# STM32G534xx register map
File version: 1.0
Registers are 32-bit, read-write, reset 0x0 unless marked. A register's access mark holds for its fields unless they carry their own. Offsets are from the block's base; [hi:lo] are bit positions; {n}, {i} and the like mark numbered series.

## RCC — Reset and clock control (RCC)
Base 0x44020C00
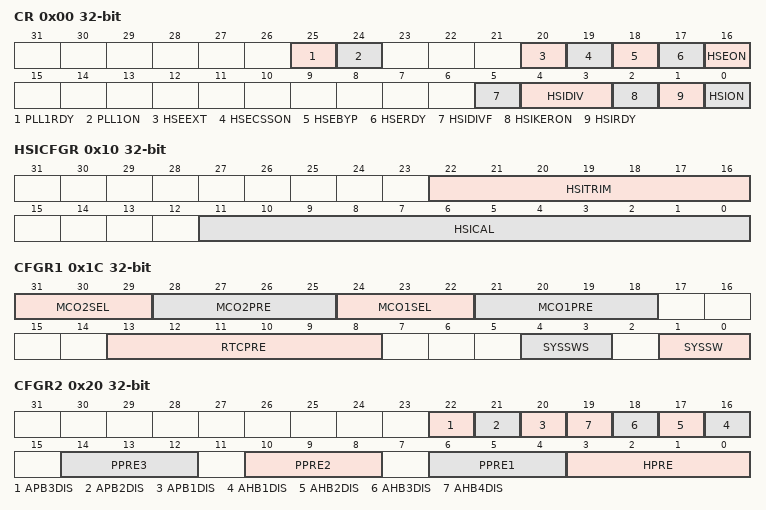
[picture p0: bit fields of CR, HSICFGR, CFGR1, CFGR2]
0x00 CR — RCC clock control register
  [25] PLL1RDY — PLL1 clock ready flag
  [24] PLL1ON — PLL1 enable
  [20] HSEEXT
  [19] HSECSSON
  [18] HSEBYP — HSE clock bypass
  [17] HSERDY — HSE clock ready flag
  [16] HSEON — HSE clock enable
  [5] HSIDIVF — HSI divider flag
  [4:3] HSIDIV — HSI clock divider
  [2] HSIKERON — HSI clock enable in Stop mode
  [1] HSIRDY — HSI clock ready flag
  [0] HSION — HSI clock enable
0x10 HSICFGR — RCC HSI calibration register
  [22:16] HSITRIM — HSI clock trimming
  [11:0] HSICAL — HSI clock calibration
0x1C CFGR1 — RCC clock configuration register1
  [31:29] MCO2SEL — microcontroller clock output 2
  [28:25] MCO2PRE — MCO2 prescaler
  [24:22] MCO1SEL — Microcontroller clock output 1
  [21:18] MCO1PRE — MCO1 prescaler
  [13:8] RTCPRE
  [4:3] SYSSWS — system clock switch status
  [1:0] SYSSW
0x20 CFGR2 — RCC CPU domain clock configuration register 2
  [22] APB3DIS — APB3 clock disable value
  [21] APB2DIS — APB2 clock disable value
  [20] APB1DIS — APB1 clock disable value
  [n+15] AHB{n}DIS (n=1..4) — AHB{n} clock disable
  [14:12] PPRE3 — APB low-speed prescaler (APB3)
  [10:8] PPRE2 — APB high-speed prescaler (APB2)
  [6:4] PPRE1 — APB low-speed prescaler (APB1)
  [3:0] HPRE — AHB prescaler
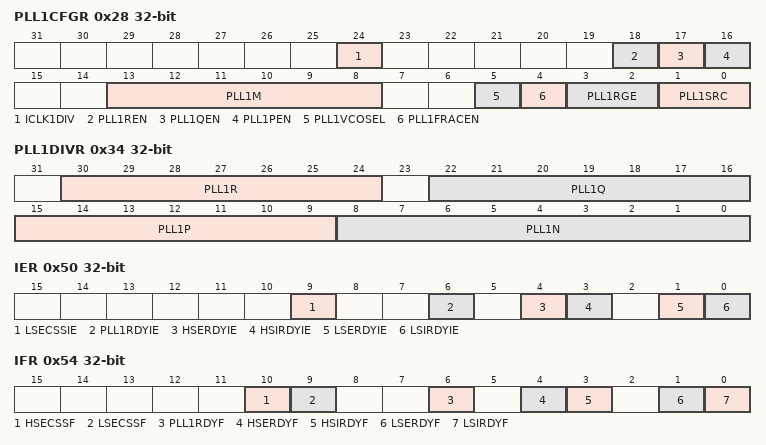
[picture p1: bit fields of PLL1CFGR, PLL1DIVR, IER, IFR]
0x28 PLL1CFGR — RCC PLL clock source selection register
  [24] ICLK1DIV — Intermediate clock 1 division
  [18] PLL1REN
  [17] PLL1QEN — PLL1 DIVQ divider output enable
  [16] PLL1PEN — PLL1 DIVP divider output enable
  [13:8] PLL1M — Prescaler for PLL1
  [5] PLL1VCOSEL — PLL1 VCO selection
  [4] PLL1FRACEN — PLL1 fractional latch enable
  [3:2] PLL1RGE — PLL1 input frequency range
  [1:0] PLL1SRC
0x34 PLL1DIVR — RCC PLL1 divider register
  [30:24] PLL1R — PLL1 DIVR division factor
  [22:16] PLL1Q — PLL1 DIVQ division factor
  [15:9] PLL1P — PLL1 DIVP division factor
  [8:0] PLL1N
0x38 PLL1FRACR — RCC PLL1 fractional divider register
  [15:3] PLL1FRACN
0x50 IER — RCC interrupt enable register
  [9] LSECSSIE
  [6] PLL1RDYIE — PLL1 ready interrupt enable
  [4] HSERDYIE — HSE ready interrupt enable
  [3] HSIRDYIE — HSI ready interrupt enable
  [1] LSERDYIE — LSE ready interrupt enable
  [0] LSIRDYIE — LSI ready interrupt enable
0x54 IFR ro — RCC interrupt flag register
  [10] HSECSSF
  [9] LSECSSF
  [6] PLL1RDYF — PLL1 ready interrupt flag
  [4] HSERDYF — HSE ready interrupt flag
  [3] HSIRDYF — HSI ready interrupt flag
  [1] LSERDYF — LSE ready interrupt flag
  [0] LSIRDYF — LSI ready interrupt flag
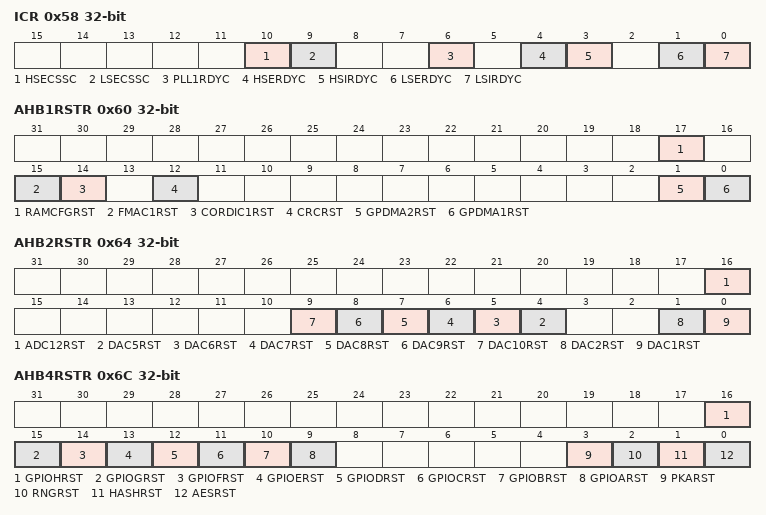
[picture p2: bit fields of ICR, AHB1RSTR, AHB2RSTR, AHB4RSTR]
0x58 ICR — RCC Interrupt clear register
  [10] HSECSSC
  [9] LSECSSC
  [6] PLL1RDYC — PLL1 ready interrupt clear
  [4] HSERDYC — HSE ready interrupt clear
  [3] HSIRDYC — HSI ready interrupt clear
  [1] LSERDYC — LSE ready interrupt clear
  [0] LSIRDYC — LSI ready interrupt clear
0x60 AHB1RSTR — RCC AHB1 reset register
  [17] RAMCFGRST — RAMCFG block reset
  [15] FMAC1RST — FMAC1 block reset
  [14] CORDIC1RST — CORDIC1 block reset
  [12] CRCRST
  [1] GPDMA2RST — GPDMA2 block reset
  [0] GPDMA1RST — GPDMA1 block reset
0x64 AHB2RSTR — RCC AHB2 peripheral reset register
  [16] ADC12RST — ADC1 and 2 blocks reset
  [n-1] DAC{n}RST (n=5..10) — DAC{n} block reset
  [1] DAC2RST — DAC2 block reset
  [0] DAC1RST — DAC1 block reset
0x6C AHB4RSTR — RCC AHB4 peripheral reset register
  [16] GPIOHRST — GPIOH block reset
  [15] GPIOGRST — GPIOG block reset
  [14] GPIOFRST — GPIOF block reset
  [13] GPIOERST — GPIOE block reset
  [12] GPIODRST — GPIOD block reset
  [11] GPIOCRST — GPIOC block reset
  [10] GPIOBRST — GPIOB block reset
  [9] GPIOARST — GPIOA block reset
  [3] PKARST — PKA block reset
  [2] RNGRST — RNG block reset
  [1] HASHRST — HASH block reset
  [0] AESRST — AES block reset
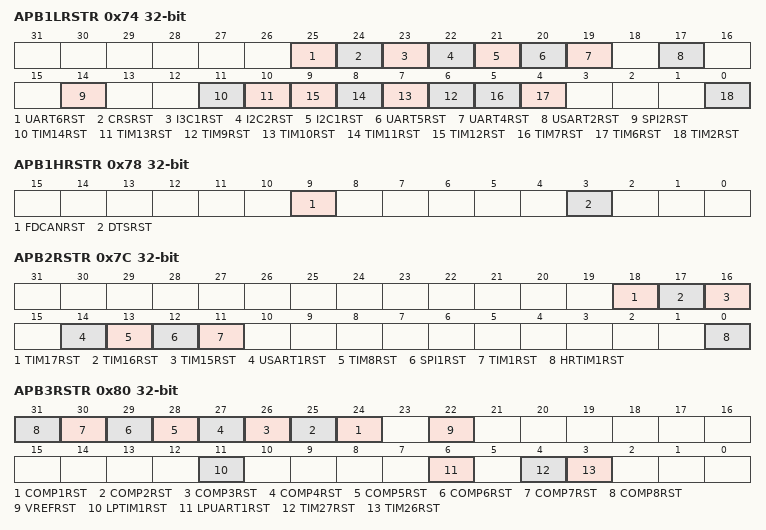
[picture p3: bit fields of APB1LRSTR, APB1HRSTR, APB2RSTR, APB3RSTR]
0x74 APB1LRSTR — RCC APB1 peripheral low reset register
  [25] UART6RST — UART6 block reset
  [24] CRSRST — CRS block reset
  [23] I3C1RST — I3C1 block reset
  [22] I2C2RST — I2C2 block reset
  [21] I2C1RST — I2C1 block reset
  [20] UART5RST — UART5 block reset
  [19] UART4RST — UART4 block reset
  [17] USART2RST — USART2 block reset
  [14] SPI2RST — SPI2 block reset
  [11] TIM14RST — TIM14 block reset
  [10] TIM13RST — TIM13 block reset
  [n-3] TIM{n}RST (n=9..12) — TIM12 block reset
  [5] TIM7RST — TIM7 block reset
  [4] TIM6RST — TIM6 block reset
  [0] TIM2RST — TIM2 block reset
0x78 APB1HRSTR — RCC APB1 peripheral high reset register
  [9] FDCANRST
  [3] DTSRST — DTS block reset
0x7C APB2RSTR — RCC APB2 peripheral reset register
  [18] TIM17RST — TIM17 block reset
  [17] TIM16RST — TIM16 block reset
  [16] TIM15RST — TIM15 block reset
  [14] USART1RST — USART1 block reset
  [13] TIM8RST — TIM8 block reset
  [12] SPI1RST — SPI1 block reset
  [11] TIM1RST — TIM1 block reset
  [0] HRTIM1RST — HRTIM1 block reset
0x80 APB3RSTR — RCC APB3 peripheral reset register
  [n+23] COMP{n}RST (n=1..8) — COMP{n} block reset
  [22] VREFRST — VREFBUF block reset
  [11] LPTIM1RST — LPTIM1 block reset
  [6] LPUART1RST — LPUART1 block reset
  [4] TIM27RST — TIM27 block reset
  [3] TIM26RST — TIM26 block reset
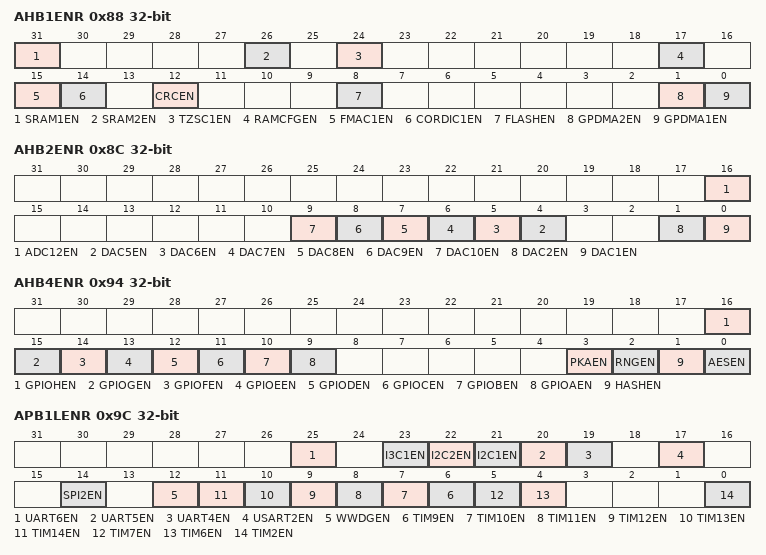
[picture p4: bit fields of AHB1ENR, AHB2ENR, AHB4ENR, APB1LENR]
0x88 AHB1ENR — RCC AHB1 peripheral clock enable register
  [31] SRAM1EN — SRAM1 clock enable
  [26] SRAM2EN — SRAM2 clock enable
  [24] TZSC1EN — TZSC1 clock enable
  [17] RAMCFGEN — RAMCFG clock enable
  [15] FMAC1EN — FMAC1 clock enable
  [14] CORDIC1EN — CORDIC1 clock enable
  [12] CRCEN — CRC clock enable
  [8] FLASHEN
  [1] GPDMA2EN — GPDMA2 clock enable
  [0] GPDMA1EN — GPDMA1 clock enable
0x8C AHB2ENR — RCC AHB2 peripheral clock enable register
  [16] ADC12EN
  [n-1] DAC{n}EN (n=5..10) — DAC{n} clock enable
  [1] DAC2EN — DAC2 clock enable
  [0] DAC1EN — DAC1 clock enable
0x90 AHB3ENR — RCC AHB3 peripheral clock enable register
  [21] DBGCKEN — DBG clock enable
0x94 AHB4ENR — RCC AHB4 peripheral clock enable register
  [16] GPIOHEN — GPIOH clock enable
  [15] GPIOGEN — GPIOG clock enable
  [14] GPIOFEN — GPIOF clock enable
  [13] GPIOEEN — GPIOE clock enable
  [12] GPIODEN — GPIOD clock enable
  [11] GPIOCEN — GPIOC clock enable
  [10] GPIOBEN — GPIOB clock enable
  [9] GPIOAEN — GPIOA clock enable
  [3] PKAEN — PKA clock enable
  [2] RNGEN — RNG clock enable
  [1] HASHEN — HASH clock enable
  [0] AESEN — AES clock enable
0x9C APB1LENR — RCC APB1 peripheral clock enable register
  [25] UART6EN — UART6 clock enable
  [23] I3C1EN — I3C1 clock enable
  [22] I2C2EN — I2C2 clock enable
  [21] I2C1EN — I2C1 clock enable
  [20] UART5EN — UART5 clock enable
  [19] UART4EN — UART4 clock enable
  [17] USART2EN — USART2 clock enable
  [14] SPI2EN — SPI2 clock enable
  [12] WWDGEN — WWDG clock enable
  [n-3] TIM{n}EN (n=9..14) — TIM{n} clock enable
  [5] TIM7EN — TIM7 clock enable
  [4] TIM6EN — TIM6 clock enable
  [0] TIM2EN — TIM2 clock enable
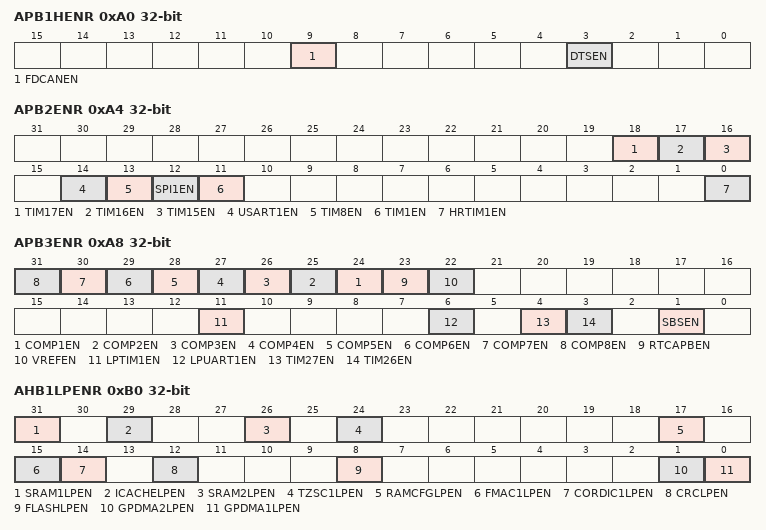
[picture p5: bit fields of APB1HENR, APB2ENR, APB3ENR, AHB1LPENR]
0xA0 APB1HENR — RCC APB1 peripheral clock enable register
  [9] FDCANEN
  [3] DTSEN — DTS clock enable
0xA4 APB2ENR — RCC APB2 peripheral clock enable register
  [18] TIM17EN — TIM17 clock enable
  [17] TIM16EN — TIM16 clock enable
  [16] TIM15EN — TIM15 clock enable
  [14] USART1EN — USART1 clock enable
  [13] TIM8EN — TIM8 clock enable
  [12] SPI1EN — SPI1 clock enable
  [11] TIM1EN — TIM1 clock enable
  [0] HRTIM1EN — HRTIM1 clock enable
0xA8 APB3ENR — RCC APB3 peripheral clock enable register
  [n+23] COMP{n}EN (n=1..8) — COMP{n} clock enable
  [23] RTCAPBEN — RTC APB interface clock enable
  [22] VREFEN — VREFBUF clock enable
  [11] LPTIM1EN — LPTIM1 clock enable
  [6] LPUART1EN — LPUART1 clock enable
  [4] TIM27EN — TIM27 clock enable
  [3] TIM26EN — TIM26 clock enable
  [1] SBSEN — SBS clock enable
0xB0 AHB1LPENR — RCC AHB1 peripheral low-power clock enable register
  [31] SRAM1LPEN, [29] ICACHELPEN, [26] SRAM2LPEN, [24] TZSC1LPEN, [17] RAMCFGLPEN, [15] FMAC1LPEN, [14] CORDIC1LPEN, [12] CRCLPEN, [8] FLASHLPEN, [1] GPDMA2LPEN, [0] GPDMA1LPEN
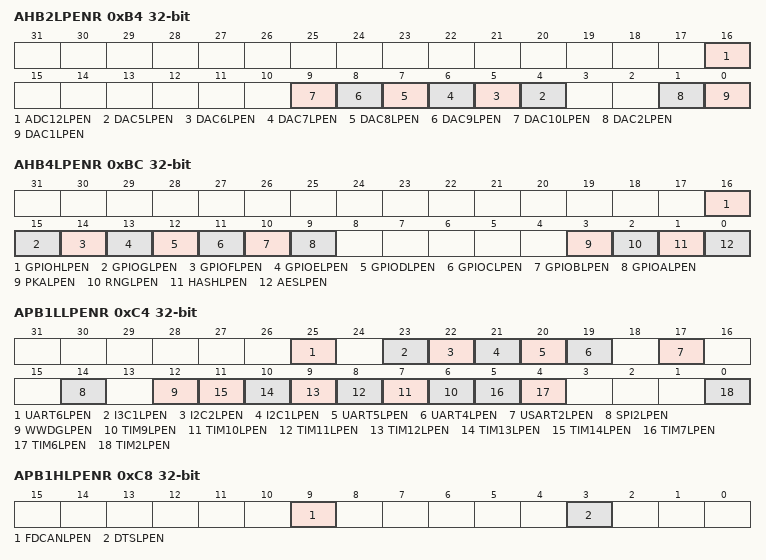
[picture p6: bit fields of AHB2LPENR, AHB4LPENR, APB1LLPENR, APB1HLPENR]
0xB4 AHB2LPENR — RCC AHB2 peripheral low-power clock enable register
  [16] ADC12LPEN, [n-1] DAC{n}LPEN (n=5..10), [1] DAC2LPEN, [0] DAC1LPEN
0xB8 AHB3LPENR — RCC AHB3 peripheral low-power clock enable register
  [21] DBGCKLPEN
0xBC AHB4LPENR — RCC AHB4 peripheral low-power clock enable register
  [16] GPIOHLPEN, [15] GPIOGLPEN, [14] GPIOFLPEN, [13] GPIOELPEN, [12] GPIODLPEN, [11] GPIOCLPEN, [10] GPIOBLPEN, [9] GPIOALPEN, [3] PKALPEN, [2] RNGLPEN, [1] HASHLPEN, [0] AESLPEN
0xC4 APB1LLPENR — RCC APB1 peripheral low-power clock enable register
  [25] UART6LPEN, [23] I3C1LPEN, [22] I2C2LPEN, [21] I2C1LPEN, [20] UART5LPEN, [19] UART4LPEN, [17] USART2LPEN, [14] SPI2LPEN, [12] WWDGLPEN, [n-3] TIM{n}LPEN (n=9..14), [5] TIM7LPEN, [4] TIM6LPEN, [0] TIM2LPEN
0xC8 APB1HLPENR — RCC APB1 peripheral low-power clock enable register
  [9] FDCANLPEN, [3] DTSLPEN
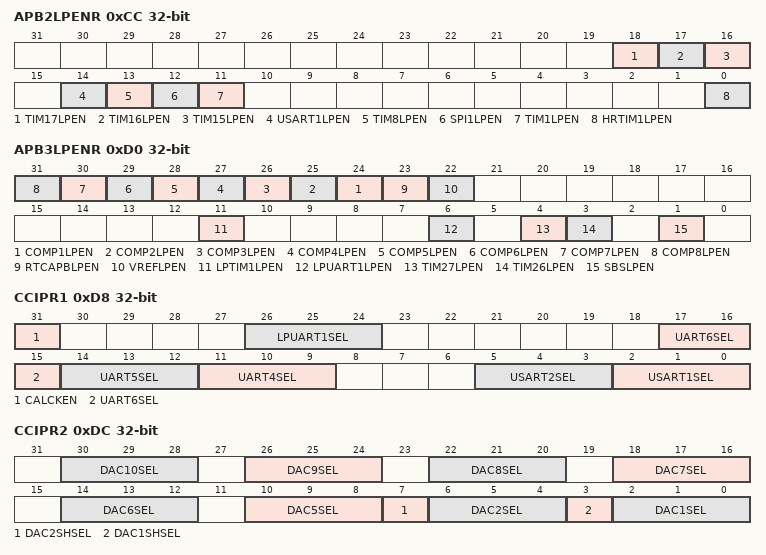
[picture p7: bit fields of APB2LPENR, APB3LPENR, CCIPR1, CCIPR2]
0xCC APB2LPENR — RCC APB2 peripheral low-power clock enable register
  [18] TIM17LPEN, [17] TIM16LPEN, [16] TIM15LPEN, [14] USART1LPEN, [13] TIM8LPEN, [12] SPI1LPEN, [11] TIM1LPEN, [0] HRTIM1LPEN
0xD0 APB3LPENR — RCC APB3 peripheral low-power clock enable register
  [n+23] COMP{n}LPEN (n=1..8), [23] RTCAPBLPEN, [22] VREFLPEN, [11] LPTIM1LPEN, [6] LPUART1LPEN, [4] TIM27LPEN, [3] TIM26LPEN, [1] SBSLPEN
0xD8 CCIPR1 — RCC kernel clock configuration register
  [31] CALCKEN — Calibration clock enable
  [26:24] LPUART1SEL
  [17:15] UART6SEL
  [14:12] UART5SEL
  [11:9] UART4SEL
  [5:3] USART2SEL
  [2:0] USART1SEL
0xDC CCIPR2 — RCC kernel clock configuration register
  [4n-10:4n-12] DAC{n}SEL (n=5..10)
  [7] DAC2SHSEL — DAC2 sample and hold clock
  [6:4] DAC2SEL
  [3] DAC1SHSEL — DAC1 sample and hold clock
  [2:0] DAC1SEL
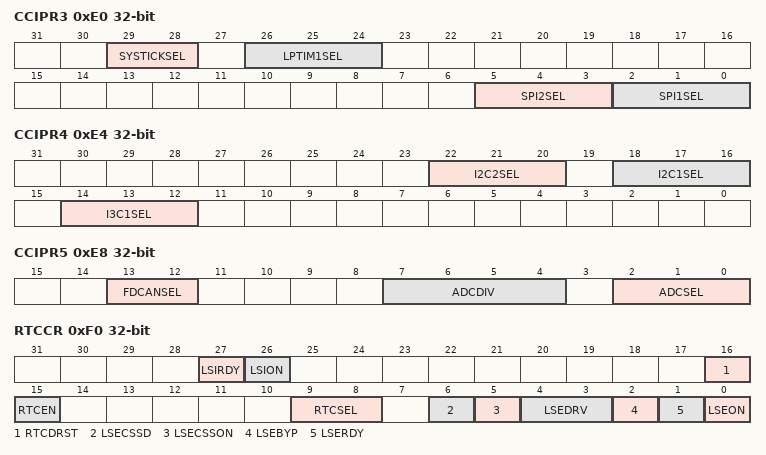
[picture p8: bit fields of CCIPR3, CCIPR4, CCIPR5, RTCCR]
0xE0 CCIPR3 — RCC kernel clock configuration register
  [29:28] SYSTICKSEL — SYSTICK clock source selection
  [26:24] LPTIM1SEL
  [5:3] SPI2SEL
  [2:0] SPI1SEL
0xE4 CCIPR4 — RCC kernel clock configuration register
  [22:20] I2C2SEL, [18:16] I2C1SEL, [14:12] I3C1SEL
0xE8 CCIPR5 — RCC kernel clock configuration register
  [13:12] FDCANSEL
  [7:4] ADCDIV — ADC clock prescaler
  [2:0] ADCSEL
0xF0 RTCCR — RCC RTC domain control register
  [27] LSIRDY — LSI oscillator ready
  [26] LSION — LSI oscillator enable
  [16] RTCDRST — RTC domain software reset
  [15] RTCEN — RTC clock enable
  [9:8] RTCSEL — RTC clock source selection
  [6] LSECSSD
  [5] LSECSSON
  [4:3] LSEDRV
  [2] LSEBYP — LSE oscillator bypass
  [1] LSERDY — LSE oscillator ready
  [0] LSEON — LSE oscillator enabled
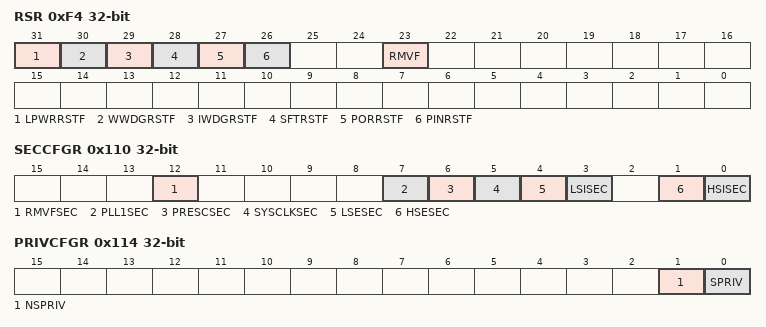
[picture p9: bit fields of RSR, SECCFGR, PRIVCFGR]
0xF4 RSR — RCC reset status register
  [31] LPWRRSTF — Low-power reset flag
  [30] WWDGRSTF — window watchdog reset flag
  [29] IWDGRSTF — independent watchdog reset flag
  [28] SFTRSTF
  [27] PORRSTF — POR reset flag
  [26] PINRSTF — pin reset flag (NRST)
  [23] RMVF — remove reset flag
0x110 SECCFGR — RCC secure configuration register
  [12] RMVFSEC — Remove reset flag security
  [7] PLL1SEC
  [6] PRESCSEC
  [5] SYSCLKSEC
  [4] LSESEC
  [3] LSISEC
  [1] HSESEC
  [0] HSISEC
0x114 PRIVCFGR — RCC privilege configuration register
  [1] NSPRIV, [0] SPRIV
